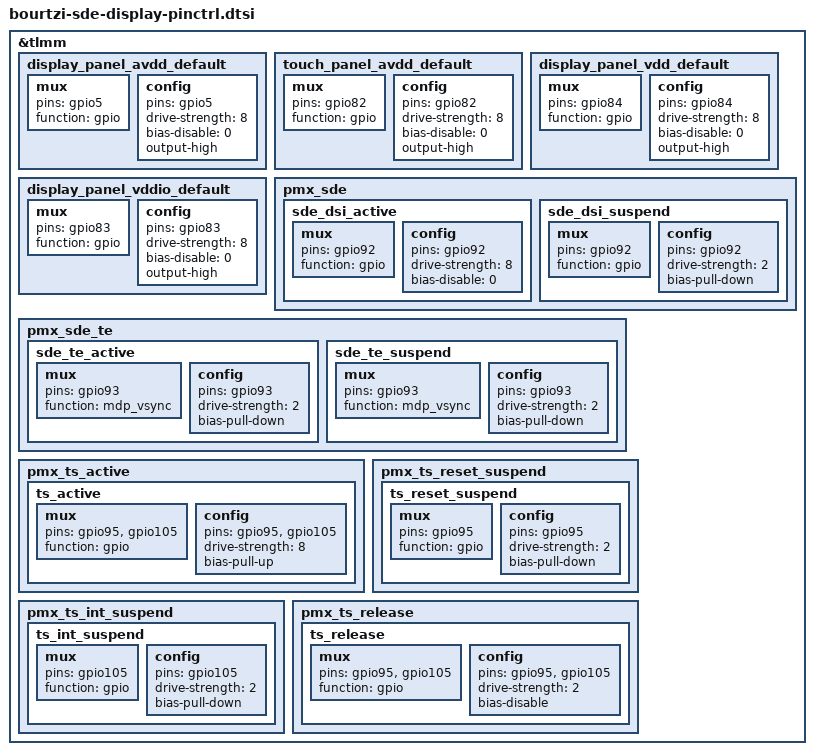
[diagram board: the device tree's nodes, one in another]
// SPDX-License-Identifier: BSD-3-Clause
/*
 * Copyright (c) Qualcomm Technologies, Inc. and/or its subsidiaries.
 */

&tlmm {
	display_panel_avdd_default: display_panel_avdd_default {
		mux {
			pins = "gpio5";
			function = "gpio";
		};

		config {
			pins = "gpio5";
			drive-strength = <8>;
			bias-disable = <0>;
			output-high;
		};
	};

	touch_panel_avdd_default: touch_panel_avdd_default {
		mux {
			pins = "gpio82";
			function = "gpio";
		};

		config {
			pins = "gpio82";
			drive-strength = <8>;
			bias-disable = <0>;
			output-high;
		};
	};

	display_panel_vdd_default: display_panel_vdd_default {
		mux {
			pins = "gpio84";
			function = "gpio";
		};

		config {
			pins = "gpio84";
			drive-strength = <8>;
			bias-disable = <0>;
			output-high;
		};
	};

	display_panel_vddio_default: display_panel_vddio_default {
		mux {
			pins = "gpio83";
			function = "gpio";
		};

		config {
			pins = "gpio83";
			drive-strength = <8>;
			bias-disable = <0>;
			output-high;
		};
	};

	pmx_sde: pmx_sde {
		sde_dsi_active: sde_dsi_active {
			mux {
				pins = "gpio92";
				function = "gpio";
			};

			config {
				pins = "gpio92";
				drive-strength = <8>;   /* 8 mA */
				bias-disable = <0>;   /* no pull */
			};
		};

		sde_dsi_suspend: sde_dsi_suspend {
			mux {
				pins = "gpio92";
				function = "gpio";
			};

			config {
				pins = "gpio92";
				drive-strength = <2>;   /* 2 mA */
				bias-pull-down;         /* PULL DOWN */
			};
		};
	};

	pmx_sde_te: pmx_sde_te {
		sde_te_active: sde_te_active {
			mux {
				pins = "gpio93";
				function = "mdp_vsync";
			};

			config {
				pins = "gpio93";
				drive-strength = <2>;   /* 2 mA */
				bias-pull-down;         /* PULL DOWN */
			};
		};

		sde_te_suspend: sde_te_suspend {
			mux {
				pins = "gpio93";
				function = "mdp_vsync";
			};

			config {
				pins = "gpio93";
				drive-strength = <2>;   /* 2 mA */
				bias-pull-down;         /* PULL DOWN */
			};
		};
	};

	pmx_ts_active {
		ts_active: ts_active {
			mux {
				pins = "gpio95", "gpio105";
				function = "gpio";
			};

			config {
				pins = "gpio95", "gpio105";
				drive-strength = <8>;
				bias-pull-up;
			};
		};
	};

	pmx_ts_reset_suspend {
		ts_reset_suspend: ts_reset_suspend {
			mux {
				pins = "gpio95";
				function = "gpio";
			};

			config {
				pins = "gpio95";
				drive-strength = <2>;
				bias-pull-down;
			};
		};
	};

	pmx_ts_int_suspend {
		ts_int_suspend: ts_int_suspend {
			mux {
				pins = "gpio105";
				function = "gpio";
			};

			config {
				pins = "gpio105";
				drive-strength = <2>;
				bias-pull-down;
			};
		};
	};

	pmx_ts_release {
		ts_release: ts_release {
			mux {
				pins = "gpio95", "gpio105";
				function = "gpio";
			};

			config {
				pins = "gpio95", "gpio105";
				drive-strength = <2>;
				bias-disable;
			};
		};
	};
};
